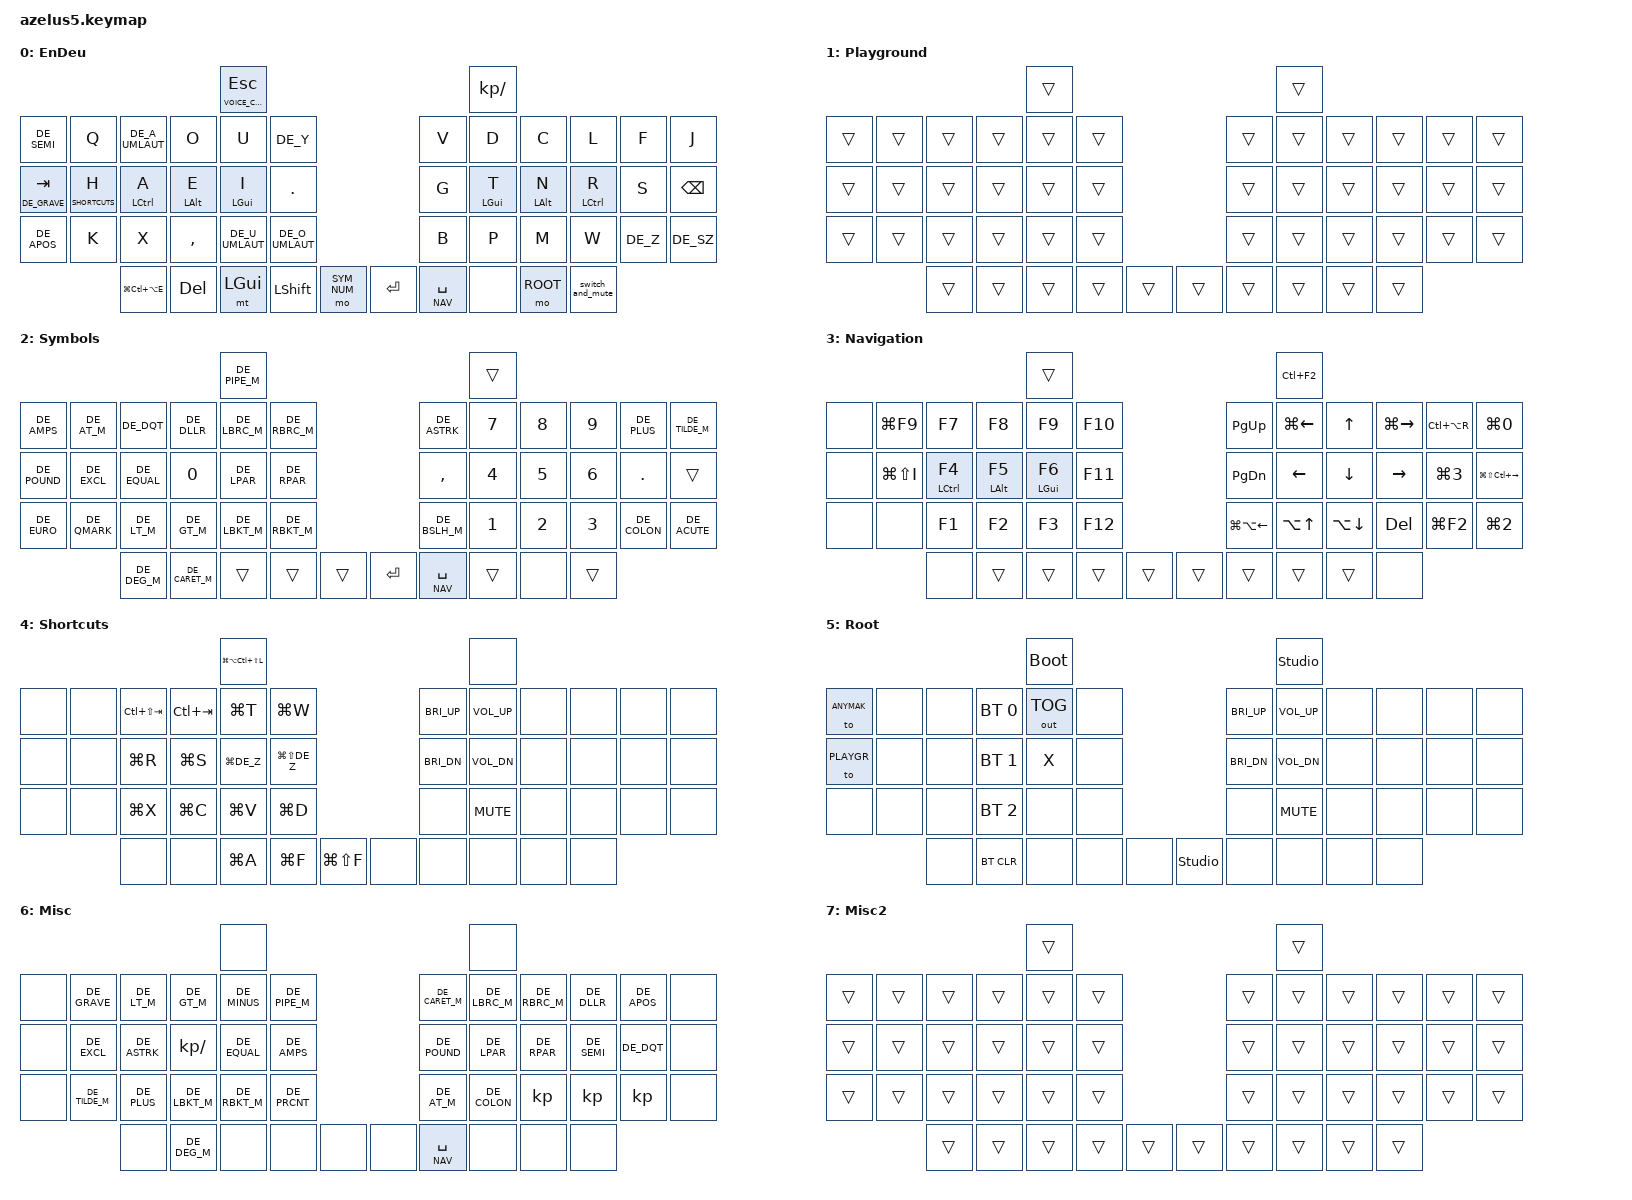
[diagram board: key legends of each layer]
#include <behaviors.dtsi>
#include <dt-bindings/zmk/bt.h>
#include <dt-bindings/zmk/keys.h>
#include <dt-bindings/zmk/outputs.h>
#include "keys_de.h"
#include "key-labels.h"

#define KEYS_L LN2 LT1 LT2 LT3 LT4 LT5 LT6 LM1 LM2 LM3 LM4 LM5 LM6 LB1 LB2 LB3 LB4 LB5 LB6  // left hand
#define KEYS_R RN2 RT1 RT2 RT3 RT4 RT5 RT6 RM1 RM2 RM3 RM4 RM5 RM6 RB1 RB2 RB3 RB4 RB5 RB6  // right hand
#define THUMBS LH0 LH1 LH2 LH3 LH4 RH0 RH1 RH2 RH3 RH4                                      // left+right thumb

/* use balanced flavor for both mod-tap and layer-tap */
&mt {
    flavor = "balanced";
};
&lt {
    flavor = "balanced";
};


/* Home Row Mod behaviors for right and left hand side.
   Based on urob's timerless home row mods: https://github.com/urob/zmk-config?tab=readme-ov-file#timeless-homerow-mods
 */
/{
    home_row_mods {
        hmr: x_HomeRowMod_right {
            compatible = "zmk,behavior-hold-tap";
            flavor = "balanced";
            tapping-term-ms = <280>;
            require-prior-idle-ms = <150>;
            hold-trigger-key-positions = <KEYS_L THUMBS>;
            hold-trigger-on-release;
            #binding-cells = <2>;
            bindings = <&kp>, <&kp>;
        };

        hml: x_HomeRowMod_left {
            compatible = "zmk,behavior-hold-tap";
            flavor = "balanced";
            tapping-term-ms = <280>;
            require-prior-idle-ms = <150>;
            hold-trigger-key-positions = <KEYS_R THUMBS LM6>;  // trigger modifier immediately when LM6 is pressed, even though it's on the same hand. Enables one-handed Command+Tab (LM6 = Tab)
            hold-trigger-on-release;
            #binding-cells = <2>;
            bindings = <&kp>, <&kp>;
        };
    };

    tap_dances {
        shifty: x_Shift_CapsWord {
            compatible = "zmk,behavior-tap-dance";
            #binding-cells = <0>;
            tapping-term-ms = <175>;
            bindings = <&kp LSHFT>, <&caps_word>;
        };
    };
};

#define SPACE_NAV       &lt NAV SPACE


// base
#define MUTE_MIC        &switch_and_mute // &kp LG(LS(M)) // when in teams-app
#define TOG_DESK_LIGHT  &kp LG(LC(LA(E)))

// nav
#define APP_MENU        &kp LC(F2)
#define START_OF_LINE   &kp LG(LEFT)
#define END_OF_LINE     &kp LG(RIGHT)

#define IJ_NEXT_ERROR   &kp LG(LS(LC(RIGHT)))
#define IJ_RUN          &kp LC(LA(R))
#define IJ_STOP         &kp LG(F2)
#define IJ_NAV_BACK     &kp LG(LA(LEFT))
#define IJ_EXPAND_SEL   &kp LA(UP)
#define IJ_SHRINK_SEL   &kp LA(DOWN)
#define IJ_TERMINAL     &kp LG(N3)
#define IJ_PROJECT      &kp LG(N0)
#define IJ_EDITOR       &kp LG(N9)
#define IJ_COMMIT       &kp LG(N2)

// control
#define NEXT_TAB        &kp LC(LS(TAB))
#define PREV_TAB        &kp LC(TAB)
#define NEW_TAB         &kp LG(T)
#define CLOSE_TAB       &kp LG(W)

#define RELOAD          &kp LG(R)
#define SAVE            &kp LG(S)
#define UNDO            &kp LG(DE_Z)
#define REDO            &kp LG(LS(DE_Z))

#define SEL_ALL         &kp LG(A)
#define FIND            &kp LG(F)
#define IJ_FIND         &kp LG(LS(F))
#define CUT             &kp LG(X)
#define COPY            &kp LG(C)
#define PASTE           &kp LG(V)
#define IJ_DEL_LINE     &kp LG(D)

#define LOCK_SCREEN     &kp LG(LA(LC(LS(L))))

#define ANYMAK    0
#define PLAYGR    1
#define SYM_NUM   2
#define NAV       3
#define SHORTCUTS 4
#define ROOT      5
#define MISC      6
#define MISC2     7


#define xxxx      &none
#define ____      &trans

/ {
    keymap {
        compatible = "zmk,keymap";

        base1 {

        /*
            A variant of EnDeu (https://github.com/rpnfan/EnDeu).
            - swap N <-> R (personal preference: redistributes finger balance more to the right middle)
            - move fairly unimportant keys like .,ÄÖXJß
        */

            bindings = <
                                                                          &mt C_VOICE_COMMAND ESC                                                                   &kp KP_SLASH
&kp DE_SEMI        &kp Q               &kp DE_A_UMLAUT   &kp O            &kp U                    &kp DE_Y                                       &kp V             &kp D               &kp C          &kp L         &kp F       &kp J
&mt DE_GRAVE TAB   &lt SHORTCUTS H     &hml LCTRL A      &hml LALT E      &hml LGUI I              &kp DOT                                        &kp G             &hmr LGUI T         &hmr LALT N    &hmr LCTRL R  &kp S       &kp BACKSPACE
&kp DE_APOS        &kp K               &kp X             &kp COMMA        &kp DE_U_UMLAUT          &kp DE_O_UMLAUT                                &kp B             &kp P               &kp M          &kp W         &kp DE_Z    &kp DE_SZ
                                       TOG_DESK_LIGHT    &kp DEL          &mt LGUI                 &kp LSHFT        &mo SYM_NUM        &kp RET    SPACE_NAV         xxxx                &mo ROOT       MUTE_MIC

            >;
            display-name = "EnDeu";
        };


        base2 {
            bindings = <
                                   ____                                        ____
 ____    ____    ____       ____   ____   ____                          ____   ____   ____   ____   ____    ____
 ____    ____    ____       ____   ____   ____                          ____   ____   ____   ____   ____    ____
 ____    ____    ____       ____   ____   ____                          ____   ____   ____   ____   ____    ____
                 ____       ____   ____   ____   ____            ____   ____   ____   ____   ____
            >;
            display-name = "Playground";
        };

        sym {

            bindings = <
                                                             &kp DE_PIPE_M                                                                ____
&kp DE_AMPS   &kp DE_AT_M    &kp DE_DQT      &kp DE_DLLR     &kp DE_LBRC_M  &kp DE_RBRC_M                                 &kp DE_ASTRK    &kp N7      &kp N8          &kp N9   &kp DE_PLUS   &kp DE_TILDE_M
&kp DE_POUND  &kp DE_EXCL    &kp DE_EQUAL    &kp N0          &kp DE_LPAR    &kp DE_RPAR                                   &kp COMMA       &kp N4      &kp N5          &kp N6   &kp DOT       ____
&kp DE_EURO   &kp DE_QMARK   &kp DE_LT_M     &kp DE_GT_M     &kp DE_LBKT_M  &kp DE_RBKT_M                                 &kp DE_BSLH_M   &kp N1      &kp N2          &kp N3   &kp DE_COLON  &kp DE_ACUTE
                             &kp DE_DEG_M    &kp DE_CARET_M  ____           ____           ____                 &kp RET   SPACE_NAV       ____        xxxx            ____
            >;
            display-name = "Symbols";
        };

        nav {

            /*
                - add left home row mods to NAV layer to avoid timing mistakes, as it allows ALT and NAV to be pressed in any order (ALT+ARROW for next/previous word on MacOS).
            */

            bindings = <
                                                           ____                                                                   APP_MENU
xxxx     &kp LG(F9)       &kp F7           &kp F8          &kp F9          &kp F10                                &kp PG_UP       START_OF_LINE     &kp UP           END_OF_LINE     IJ_RUN           IJ_PROJECT
xxxx     &kp LG(LS(I))    &hml LCTRL F4    &hml LALT F5    &hml LGUI F6    &kp F11                                &kp PG_DN       &kp LEFT          &kp DOWN         &kp RIGHT       IJ_TERMINAL      IJ_NEXT_ERROR
xxxx     xxxx             &kp F1           &kp F2          &kp F3          &kp F12                                IJ_NAV_BACK     IJ_EXPAND_SEL     IJ_SHRINK_SEL    &kp DEL         IJ_STOP          IJ_COMMIT
                          xxxx             ____            ____            ____      ____                ____     ____            ____              ____             xxxx
            >;
            display-name = "Navigation";

        };

        shortcuts {
            bindings = <
                                      LOCK_SCREEN                                                              xxxx
 xxxx    xxxx   NEXT_TAB   PREV_TAB   NEW_TAB    CLOSE_TAB                                   &kp C_BRI_UP      &kp K_VOL_UP    xxxx      xxxx    xxxx    xxxx
 xxxx    xxxx   RELOAD     SAVE       UNDO       REDO                                        &kp C_BRI_DN      &kp K_VOL_DN    xxxx      xxxx    xxxx    xxxx
 xxxx    xxxx   CUT        COPY       PASTE      IJ_DEL_LINE                                 xxxx              &kp K_MUTE      xxxx      xxxx    xxxx    xxxx
                xxxx       xxxx       SEL_ALL    FIND         IJ_FIND                xxxx    xxxx              xxxx            xxxx      xxxx
            >;
            display-name = "Shortcuts";
        };

        root {
            bindings = <
                                                 &bootloader                                                        &studio_unlock
 &to ANYMAK   xxxx    xxxx         &bt BT_SEL 0  &out OUT_TOG  xxxx                                   &kp C_BRI_UP   &kp K_VOL_UP    xxxx           xxxx   xxxx   xxxx
 &to PLAYGR   xxxx    xxxx         &bt BT_SEL 1  &kp X         xxxx                                   &kp C_BRI_DN   &kp K_VOL_DN    xxxx           xxxx   xxxx   xxxx
 xxxx         xxxx    xxxx         &bt BT_SEL 2  xxxx          xxxx                                   xxxx           &kp K_MUTE      xxxx           xxxx   xxxx   xxxx
                      xxxx         &bt BT_CLR    xxxx          xxxx    xxxx          &studio_unlock   xxxx           xxxx            xxxx           xxxx
            >;
            display-name = "Root";
        };

        misc {
            // adapted from https://getreuer.info/posts/keyboards/symbol-layer/index.html#my-symbol-layer

            bindings = <
                                                          xxxx                                                                               xxxx
xxxx   &kp DE_GRAVE     &kp DE_LT_M     &kp DE_GT_M       &kp DE_MINUS     &kp DE_PIPE_M                                   &kp DE_CARET_M    &kp DE_LBRC_M      &kp DE_RBRC_M      &kp DE_DLLR   &kp DE_APOS   xxxx
xxxx   &kp DE_EXCL      &kp DE_ASTRK    &kp KP_SLASH      &kp DE_EQUAL     &kp DE_AMPS                                     &kp DE_POUND      &kp DE_LPAR        &kp DE_RPAR        &kp DE_SEMI   &kp DE_DQT    xxxx
xxxx   &kp DE_TILDE_M   &kp DE_PLUS     &kp DE_LBKT_M     &kp DE_RBKT_M    &kp DE_PRCNT                                    &kp DE_AT_M       &kp DE_COLON       &kp                &kp           &kp           xxxx
                        xxxx            &kp DE_DEG_M      xxxx             xxxx             xxxx                 xxxx      SPACE_NAV         xxxx               xxxx               xxxx
            >;
            display-name = "Misc";
        };

        misc2 {
            bindings = <
                              ____                                        ____
 ____    ____   ____   ____   ____   ____                          ____   ____   ____   ____   ____   ____
 ____    ____   ____   ____   ____   ____                          ____   ____   ____   ____   ____   ____
 ____    ____   ____   ____   ____   ____                          ____   ____   ____   ____   ____   ____
                ____   ____   ____   ____   ____            ____   ____   ____   ____   ____
            >;
            display-name = "Misc2";
        };


        /*

                              ____                                        ____
 ____    ____   ____   ____   ____   ____                          ____   ____   ____   ____   ____   ____
 ____    ____   ____   ____   ____   ____                          ____   ____   ____   ____   ____   ____
 ____    ____   ____   ____   ____   ____                          ____   ____   ____   ____   ____   ____
                ____   ____   ____   ____   ____            ____   ____   ____   ____   ____


                              xxxx                                     xxxx
 xxxx    xxxx   xxxx   xxxx   xxxx   xxxx                       xxxx   xxxx   xxxx   xxxx   xxxx   xxxx
 xxxx    xxxx   xxxx   xxxx   xxxx   xxxx                       xxxx   xxxx   xxxx   xxxx   xxxx   xxxx
 xxxx    xxxx   xxxx   xxxx   xxxx   xxxx                       xxxx   xxxx   xxxx   xxxx   xxxx   xxxx
                xxxx   xxxx   xxxx   xxxx   xxxx         xxxx   xxxx   xxxx   xxxx   xxxx
        */
    };



    position_map {
        compatible = "zmk,physical-layout-position-map";
        complete;
        layout1: layout1 {
            physical-layout = <&physical_layout0>;
            positions = <                LN2                   RN2                >
                       ,<LT6 LT5 LT4 LT3 LT2 LT1           RT1 RT2 RT3 RT4 RT5 RT6>
                       ,<LM6 LM5 LM4 LM3 LM2 LM1           RM1 RM2 RM3 RM4 RM5 RM6>
                       ,<LB6 LB5 LB4 LB3 LB2 LB1           RB1 RB2 RB3 RB4 RB5 RB6>
                       ,<        LH4 LH3 LH2 LH1 LH0   RH0 RH1 RH2 RH3 RH4        >
            ;
            // <side> <row> <column>
            // <Left|Right>
            // <Number|Top|Middle|Bottom|tHumb>
        };
    };


    #define COMBO_TIMEOUT 30  // default=50
    #define COMBO_TIMEOUT_VERTICAL 50

    #define COMBO(NAME, KEYS, BINDINGS, LAYERS) \
        NAME { \
            timeout-ms = <COMBO_TIMEOUT>; \
            layers = <LAYERS>; \
            key-positions = <KEYS>; \
            bindings = <BINDINGS>; \
        };

    // vertical combo
    #define VOMBO(NAME, KEYS, BINDINGS, LAYERS) \
        NAME { \
            timeout-ms = <COMBO_TIMEOUT_VERTICAL>; \
            layers = <LAYERS>; \
            key-positions = <KEYS>; \
            bindings = <BINDINGS>; \
        };

    combos {
        compatible = "zmk,combos";

        COMBO(cb_anymak_bullet_point,   RT2 RT3,    &bullet_point,      ANYMAK  PLAYGR                  )  // types "* " to create bullet points in most applications
        COMBO(cb_anymak_hyphen,         RT3 RT4,    &kp DE_MINUS,       ANYMAK  PLAYGR           SYM_NUM)

        COMBO(cb_underscore,            RB3 RB4,    &kp LS(DE_MINUS),   ANYMAK  PLAYGR                  )
        COMBO(cb_vim_wq,                LT3 LT2,    &vim_x,             ANYMAK  PLAYGR                  )  // types "Esc :x" for vim

/* Combos for switching base layers:
        COMBO(cb_anymak,                LT6 LT5,    &to ANYMAK,         ANYMAK  PLAYGR                  )
        COMBO(cb_playground,            LM6 LM5,    &to PLAYGR,         ANYMAK  PLAYGR                  )
*/

        COMBO(cb_cut,                   LB4 LB5,    CUT,                ANYMAK  PLAYGR                  )
        COMBO(cb_copy,                  LB3 LB4,    COPY,               ANYMAK  PLAYGR                  )
        COMBO(cb_paste,                 LB2 LB3,    PASTE,              ANYMAK  PLAYGR                  )

        COMBO(cb_lambda,                LT3 LT2,    &lambda,                                     SYM_NUM)  // types "->", e.g. for lambda syntax in Java
        COMBO(cb_sym_percent,           LT4 LT3,    &kp DE_PRCNT,                                SYM_NUM)


/* Deactivate vertical combos
        VOMBO(cb_anymak_ampersand,      LT5 LM5,    &kp DE_AMPS,        ANYMAK  PLAYGR                  )
        VOMBO(cb_anymak_hash,           LM5 LB5,    &kp DE_POUND,       ANYMAK  PLAYGR                  )
        VOMBO(cb_anymak_euro,           LM3 LB3,    &kp DE_EURO,        ANYMAK  PLAYGR                  )
*/

    };

    macros {
            bullet_point: x_BulletPoint {
                compatible = "zmk,behavior-macro";
                #binding-cells = <0>;
                bindings
                    = <&macro_tap &kp DE_ASTERISK &kp SPACE>
                    ;
            };
            lambda: x_Lambda {
                compatible = "zmk,behavior-macro";
                #binding-cells = <0>;
                bindings
                    = <&macro_tap &kp DE_MINUS &kp DE_GT_M>
                    ;
            };
            switch_and_mute: x_SwitchAndMute {
                compatible = "zmk,behavior-macro";
                #binding-cells = <0>;
                bindings
                    = <&macro_press &kp LGUI &kp LALT &kp LCTL>     // switch to Teams (custom MacOS shortcut)
                    , <&macro_tap &kp T>
                    , <&macro_release &kp LGUI &kp LALT &kp LCTL>
                    , <&macro_wait_time 50>
                    , <&macro_press &kp LGUI &kp LSFT>              // mute (Teams shortcut)
                    , <&macro_tap &kp M>
                    , <&macro_release &kp LGUI &kp LSFT>
                    ;
            };
            vim_x: x_Vim_WQ {
                compatible = "zmk,behavior-macro";
                #binding-cells = <0>;
                bindings
                    = <&macro_tap &kp ESC &kp DE_COLON &kp X>
                    ;
            };
    };


/*
    conditional_layers {
        compatible = "zmk,conditional-layers";
        sym_tri_layer {
            if-layers = <LINUX SYM_NUM>;
            then-layer = <SYM_NUM_LIN>;
        };
    };
    */

    physical_layout0: default_layout {
        compatible = "zmk,physical-layout";
        display-name = "Physical Layout";
        transform = <&matrix_transform0>;
        kscan = <&kscan0>;
        keys =  <&key_physical_attrs 100 100  400    40      1000     700   450>
               ,<&key_physical_attrs 100 100  900    40    (-1000)    700   450>

               ,<&key_physical_attrs 100 100    0    170     1000     700   450>
               ,<&key_physical_attrs 100 100  100    160     1000     700   450>
               ,<&key_physical_attrs 100 100  200    120     1000     700   450>
               ,<&key_physical_attrs 100 100  300    100     1000     700   450>
               ,<&key_physical_attrs 100 100  400    140     1000     700   450>
               ,<&key_physical_attrs 100 100  500    150     1000     700   450>
               ,<&key_physical_attrs 100 100  800    150   (-1000)    700   450>
               ,<&key_physical_attrs 100 100  900    140   (-1000)    700   450>
               ,<&key_physical_attrs 100 100 1000    100   (-1000)    700   450>
               ,<&key_physical_attrs 100 100 1100    120   (-1000)    700   450>
               ,<&key_physical_attrs 100 100 1200    160   (-1000)    700   450>
               ,<&key_physical_attrs 100 100 1300    170   (-1000)    700   450>

               ,<&key_physical_attrs 100 100    0    270     1000     700   450>
               ,<&key_physical_attrs 100 100  100    260     1000     700   450>
               ,<&key_physical_attrs 100 100  200    220     1000     700   450>
               ,<&key_physical_attrs 100 100  300    200     1000     700   450>
               ,<&key_physical_attrs 100 100  400    240     1000     700   450>
               ,<&key_physical_attrs 100 100  500    250     1000     700   450>
               ,<&key_physical_attrs 100 100  800    250   (-1000)    700   450>
               ,<&key_physical_attrs 100 100  900    240   (-1000)    700   450>
               ,<&key_physical_attrs 100 100 1000    200   (-1000)    700   450>
               ,<&key_physical_attrs 100 100 1100    220   (-1000)    700   450>
               ,<&key_physical_attrs 100 100 1200    260   (-1000)    700   450>
               ,<&key_physical_attrs 100 100 1300    270   (-1000)    700   450>

               ,<&key_physical_attrs 100 100    0    370     1000     700   450>
               ,<&key_physical_attrs 100 100  100    360     1000     700   450>
               ,<&key_physical_attrs 100 100  200    320     1000     700   450>
               ,<&key_physical_attrs 100 100  300    300     1000     700   450>
               ,<&key_physical_attrs 100 100  400    340     1000     700   450>
               ,<&key_physical_attrs 100 100  500    350     1000     700   450>
               ,<&key_physical_attrs 100 100  800    350   (-1000)    700   450>
               ,<&key_physical_attrs 100 100  900    340   (-1000)    700   450>
               ,<&key_physical_attrs 100 100 1000    300   (-1000)    700   450>
               ,<&key_physical_attrs 100 100 1100    320   (-1000)    700   450>
               ,<&key_physical_attrs 100 100 1200    360   (-1000)    700   450>
               ,<&key_physical_attrs 100 100 1300    370   (-1000)    700   450>

               ,<&key_physical_attrs 100 100  200    430     1000     700   450>
               ,<&key_physical_attrs 100 100  300    410     1000     700   450>
               ,<&key_physical_attrs 100 100  400    480     1000     700   450>
               ,<&key_physical_attrs 100 100  500    480     1000     700   450>
               ,<&key_physical_attrs 100 100  600    480     1000     700   450>
               ,<&key_physical_attrs 100 100  700    480   (-1000)    700   450>
               ,<&key_physical_attrs 100 100  800    480   (-1000)    700   450>
               ,<&key_physical_attrs 100 100  900    480   (-1000)    700   450>
               ,<&key_physical_attrs 100 100 1000    410   (-1000)    700   450>
               ,<&key_physical_attrs 100 100 1100    430   (-1000)    700   450>
            ;
        };


};
